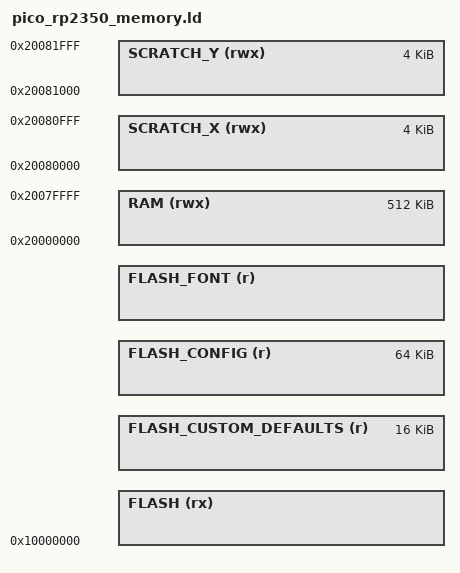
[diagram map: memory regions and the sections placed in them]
/* Memory regions */

FLASH_ORIGIN = 0x10000000;
CONFIG_LENGTH = 64K;
/* Board-config-as-custom-defaults blob (USE_CUSTOM_DEFAULTS, cli.c): kept at
 * a deterministic position (end of flash, just before config/font) so build
 * tooling can locate it per target variant without parsing the ELF. */
CUSTOM_DEFAULTS_LENGTH = 16K;
FLASH_OTHER_LENGTH = PRIMARY_FLASH_LENGTH - CONFIG_LENGTH - FONT_LENGTH - CUSTOM_DEFAULTS_LENGTH;

MEMORY
{
    FLASH (rx)                 : ORIGIN = FLASH_ORIGIN, LENGTH = FLASH_OTHER_LENGTH
    FLASH_CUSTOM_DEFAULTS (r)  : ORIGIN = FLASH_ORIGIN + FLASH_OTHER_LENGTH, LENGTH = CUSTOM_DEFAULTS_LENGTH
    FLASH_CONFIG (r)           : ORIGIN = FLASH_ORIGIN + FLASH_OTHER_LENGTH + CUSTOM_DEFAULTS_LENGTH, LENGTH = CONFIG_LENGTH
    FLASH_FONT (r)             : ORIGIN = FLASH_ORIGIN + FLASH_OTHER_LENGTH + CUSTOM_DEFAULTS_LENGTH + CONFIG_LENGTH, LENGTH = FONT_LENGTH
    RAM(rwx) : ORIGIN =  0x20000000, LENGTH = 512k
    SCRATCH_X(rwx) : ORIGIN = 0x20080000, LENGTH = 4k
    SCRATCH_Y(rwx) : ORIGIN = 0x20081000, LENGTH = 4k
}
